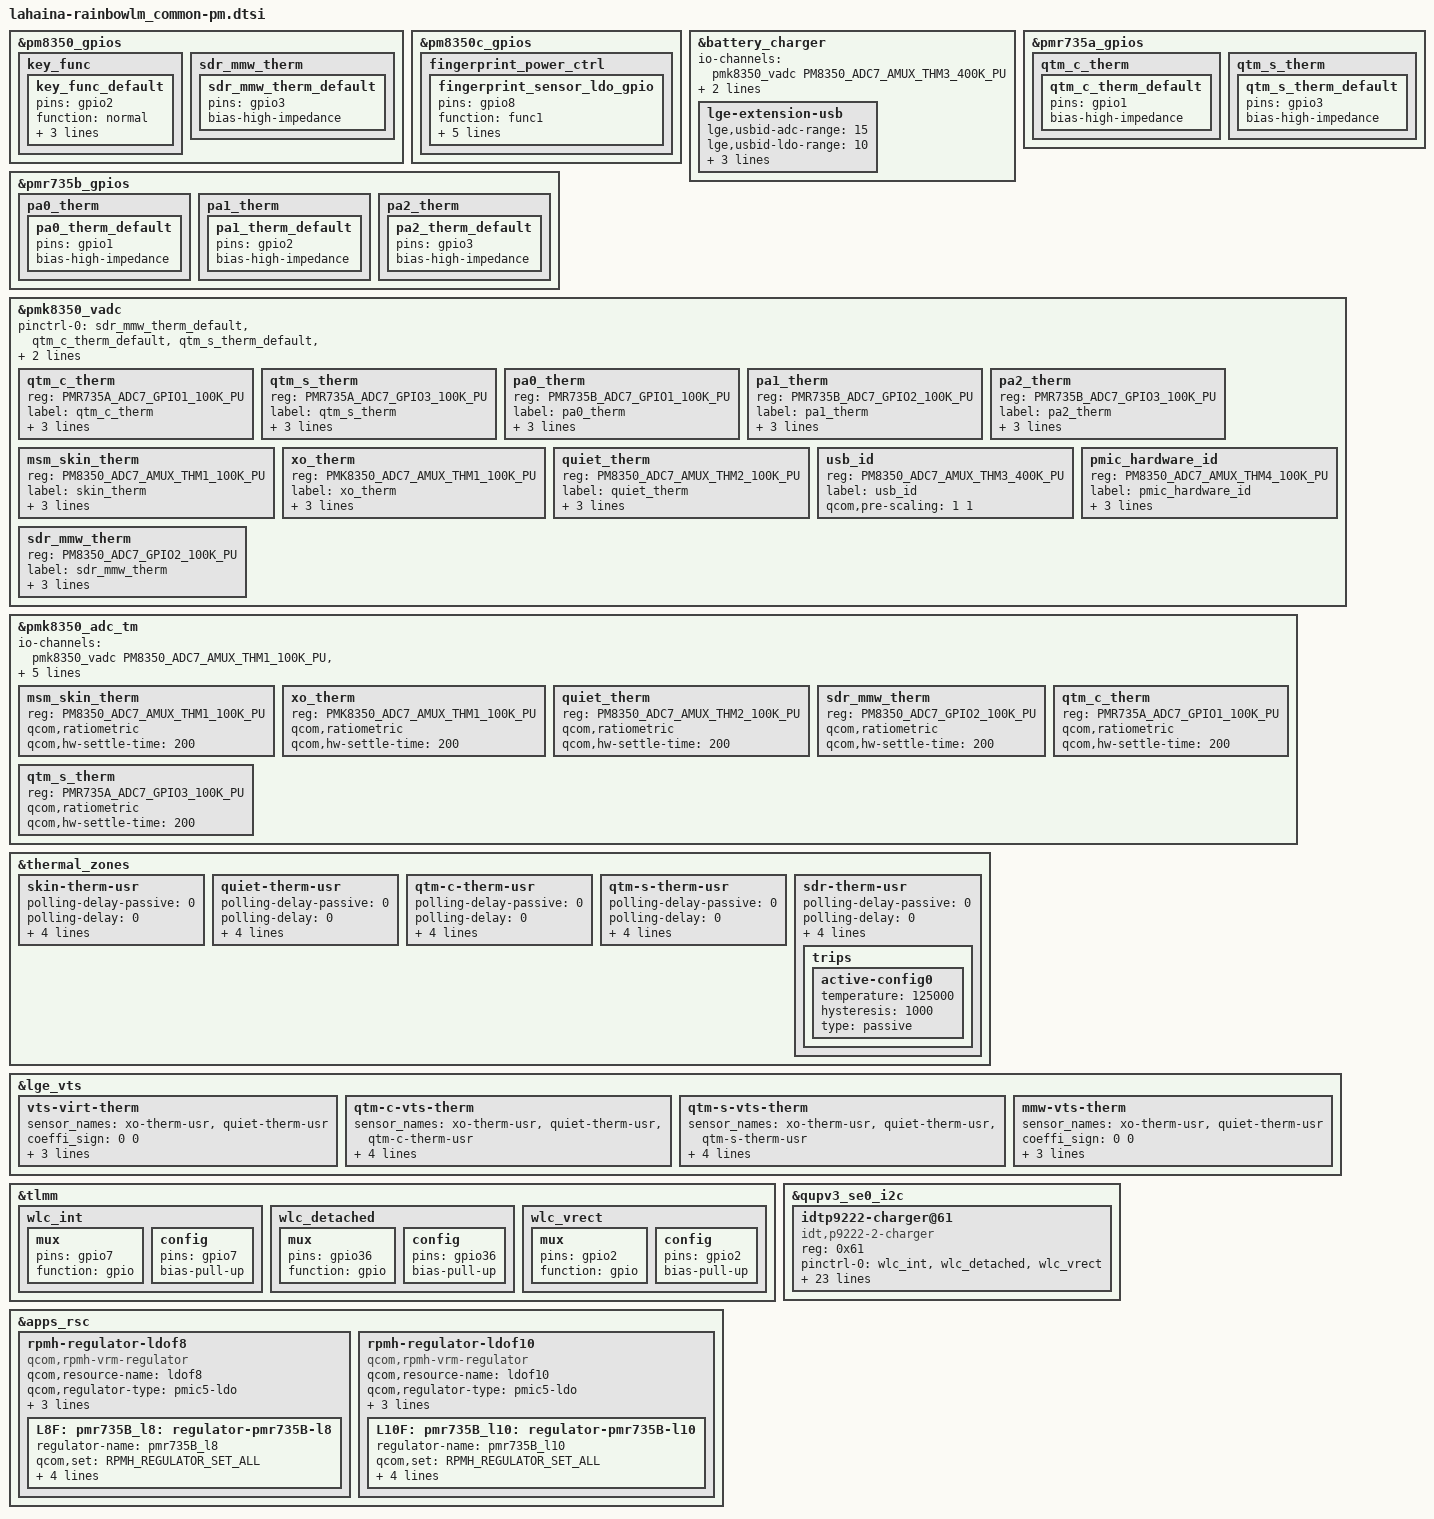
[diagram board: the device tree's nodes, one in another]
#include "../../lahaina_common/lahaina_common-pm.dtsi"
#include "../../lahaina_common/lahaina_common-veneer.dtsi"
#include "lahaina-rainbowlm_common-veneer.dtsi"
#include <dt-bindings/regulator/qcom,rpmh-regulator-levels.h>

&pm8350_gpios {
    key_func {
	key_func_default: key_func_default {
	    pins = "gpio2";
	    function = "normal";
	    input-enable;
	    bias-pull-up;
	    power-source = <0>;
	};
    };

	sdr_mmw_therm {
		sdr_mmw_therm_default: sdr_mmw_therm_default {
			pins = "gpio3";
			bias-high-impedance;
		};
	};
};

#if 1    // LGE_RAINBOW
&pm8350c_gpios {
    fingerprint_power_ctrl {
        fingerprint_sensor_ldo_gpio: fingerprint_sensor_ldo_gpio {
            pins = "gpio8";
            function = "func1";
            input-disable;
            output-enable;
            bias-disable;
            power-source = <1>;	/* 1.8V */
            qcom,drive-strength = <2>;
        };
    };
};
#endif

&battery_charger {
	io-channels = <&pmk8350_vadc PM8350_ADC7_AMUX_THM3_400K_PU>;
	io-channel-names = "usb_id";

	/delete-property/ qcom,thermal-mitigation;

	lge,hvdcp-disable-jp;
	lge,pcb-battery-id = <390000>;
	lge-extension-usb {
		lge,usbid-adc-range = <15>;		// ADC margin (pct unit)
		lge,usbid-ldo-range = <10>;		// LDO margin (pct unit)
		lge,usbid-pullup-mvol = <1800>;		// Pull-up voltage
		lge,usbid-pullup-kohm = <400>;		// Pull-up resistance
		lge,usbid-parallel-kohm = <(-1)>;	// Pull-up resistance
	};
};

&pmr735a_gpios {
	qtm_c_therm {
		qtm_c_therm_default: qtm_c_therm_default {
			pins = "gpio1";
			bias-high-impedance;
		};
	};

	qtm_s_therm {
		qtm_s_therm_default: qtm_s_therm_default {
			pins = "gpio3";
			bias-high-impedance;
		};
	};
};

&pmr735b_gpios {
	pa0_therm {
		pa0_therm_default: pa0_therm_default {
			pins = "gpio1";
			bias-high-impedance;
		};
	};

	pa1_therm {
		pa1_therm_default: pa1_therm_default {
			pins = "gpio2";
			bias-high-impedance;
		};
	};

	pa2_therm {
		pa2_therm_default: pa2_therm_default {
			pins = "gpio3";
			bias-high-impedance;
		};
	};
};

&pmk8350_vadc {
	pinctrl-names = "default";
	pinctrl-0 = <&sdr_mmw_therm_default
		&qtm_c_therm_default
		&qtm_s_therm_default
		&pa0_therm_default
		&pa1_therm_default
		&pa2_therm_default>;

	qtm_c_therm {
		reg = <PMR735A_ADC7_GPIO1_100K_PU>;
		label = "qtm_c_therm";
		qcom,ratiometric;
		qcom,hw-settle-time = <200>;
		qcom,pre-scaling = <1 1>;
	};

	qtm_s_therm {
		reg = <PMR735A_ADC7_GPIO3_100K_PU>;
		label = "qtm_s_therm";
		qcom,ratiometric;
		qcom,hw-settle-time = <200>;
		qcom,pre-scaling = <1 1>;
	};

	pa0_therm {
		reg = <PMR735B_ADC7_GPIO1_100K_PU>;
		label = "pa0_therm";
		qcom,ratiometric;
		qcom,hw-settle-time = <200>;
		qcom,pre-scaling = <1 1>;
	};

	pa1_therm {
		reg = <PMR735B_ADC7_GPIO2_100K_PU>;
		label = "pa1_therm";
		qcom,ratiometric;
		qcom,hw-settle-time = <200>;
		qcom,pre-scaling = <1 1>;
	};

	pa2_therm {
		reg = <PMR735B_ADC7_GPIO3_100K_PU>;
		label = "pa2_therm";
		qcom,ratiometric;
		qcom,hw-settle-time = <200>;
		qcom,pre-scaling = <1 1>;
	};

	msm_skin_therm {
		reg = <PM8350_ADC7_AMUX_THM1_100K_PU>;
		label = "skin_therm";
		qcom,ratiometric;
		qcom,hw-settle-time = <200>;
		qcom,pre-scaling = <1 1>;
	};

	xo_therm {
		reg = <PMK8350_ADC7_AMUX_THM1_100K_PU>;
		label = "xo_therm";
		qcom,ratiometric;
		qcom,hw-settle-time = <200>;
		qcom,pre-scaling = <1 1>;
	};

	quiet_therm {
		reg = <PM8350_ADC7_AMUX_THM2_100K_PU>;
		label = "quiet_therm";
		qcom,ratiometric;
		qcom,hw-settle-time = <200>;
		qcom,pre-scaling = <1 1>;
	};

	usb_id {
		reg = <PM8350_ADC7_AMUX_THM3_400K_PU>;
		label = "usb_id";
		qcom,pre-scaling = <1 1>;
	};

	pmic_hardware_id {
		reg = <PM8350_ADC7_AMUX_THM4_100K_PU>;
		label = "pmic_hardware_id";
		qcom,ratiometric;
		qcom,hw-settle-time = <100>;
		qcom,pre-scaling = <1 1>;
	};

	sdr_mmw_therm {
		reg = <PM8350_ADC7_GPIO2_100K_PU>;
		label = "sdr_mmw_therm";
		qcom,ratiometric;
		qcom,hw-settle-time = <200>;
		qcom,pre-scaling = <1 1>;
	};
};

&pmk8350_adc_tm {
	io-channels = <&pmk8350_vadc PM8350_ADC7_AMUX_THM1_100K_PU>,
		<&pmk8350_vadc PMK8350_ADC7_AMUX_THM1_100K_PU>,
		<&pmk8350_vadc PM8350_ADC7_AMUX_THM2_100K_PU>,
		<&pmk8350_vadc PM8350_ADC7_GPIO2_100K_PU>,
		<&pmk8350_vadc PMR735A_ADC7_GPIO1_100K_PU>,
		<&pmk8350_vadc PMR735A_ADC7_GPIO3_100K_PU>;

	msm_skin_therm {
		reg = <PM8350_ADC7_AMUX_THM1_100K_PU>;
		qcom,ratiometric;
		qcom,hw-settle-time = <200>;
	};

	xo_therm {
		reg = <PMK8350_ADC7_AMUX_THM1_100K_PU>;
		qcom,ratiometric;
		qcom,hw-settle-time = <200>;
	};

	quiet_therm {
		reg = <PM8350_ADC7_AMUX_THM2_100K_PU>;
		qcom,ratiometric;
		qcom,hw-settle-time = <200>;
	};

	sdr_mmw_therm {
		reg = <PM8350_ADC7_GPIO2_100K_PU>;
		qcom,ratiometric;
		qcom,hw-settle-time = <200>;
	};

	qtm_c_therm {
		reg = <PMR735A_ADC7_GPIO1_100K_PU>;
		qcom,ratiometric;
		qcom,hw-settle-time = <200>;
	};

	qtm_s_therm {
		reg = <PMR735A_ADC7_GPIO3_100K_PU>;
		qcom,ratiometric;
		qcom,hw-settle-time = <200>;
	};

};

&thermal_zones {
	skin-therm-usr {
		polling-delay-passive = <0>;
		polling-delay = <0>;
		thermal-governor = "user_space";
		thermal-sensors = <&pmk8350_adc_tm PM8350_ADC7_AMUX_THM1_100K_PU>;
		wake-capable-sensor;
	};

	quiet-therm-usr {
		polling-delay-passive = <0>;
		polling-delay = <0>;
		thermal-governor = "user_space";
		thermal-sensors = <&pmk8350_adc_tm PM8350_ADC7_AMUX_THM2_100K_PU>;
		wake-capable-sensor;
	};

	qtm-c-therm-usr {
		polling-delay-passive = <0>;
		polling-delay = <0>;
		thermal-governor = "user_space";
		thermal-sensors = <&pmk8350_adc_tm PMR735A_ADC7_GPIO1_100K_PU>;
		wake-capable-sensor;
	};

	qtm-s-therm-usr {
		polling-delay-passive = <0>;
		polling-delay = <0>;
		thermal-governor = "user_space";
		thermal-sensors = <&pmk8350_adc_tm PMR735A_ADC7_GPIO3_100K_PU>;
		wake-capable-sensor;
	};

	sdr-therm-usr {
		polling-delay-passive = <0>;
		polling-delay = <0>;
		thermal-governor = "user_space";
		thermal-sensors = <&pmk8350_adc_tm PM8350_ADC7_GPIO2_100K_PU>;
		wake-capable-sensor;
		trips {
			active-config0 {
				temperature = <125000>;
				hysteresis = <1000>;
				type = "passive";
			};
		};
	};
};


&lge_vts {
	vts-virt-therm {
		sensor_names = "xo-therm-usr", "quiet-therm-usr";
		coeffi_sign = <0 0>;
		coefficients = <391 388>;
		avg_denominator = <1000>;
		avg_offset = <4795>;
	};
	qtm-c-vts-therm {
		sensor_names = "xo-therm-usr", "quiet-therm-usr", "qtm-c-therm-usr";
		coeffi_sign = <0 0 0>;
		coefficients = <80 612 119>;
		avg_denominator = <1000>;
		avg_offset = <3713>;
	};
	qtm-s-vts-therm {
		sensor_names = "xo-therm-usr", "quiet-therm-usr", "qtm-s-therm-usr";
		coeffi_sign = <0 0 1>;
		coefficients = <877 84 212>;
		avg_denominator = <1000>;
		avg_offset = <4541>;
	};
	mmw-vts-therm {
		sensor_names = "xo-therm-usr", "quiet-therm-usr";
		coeffi_sign = <0 0>;
		coefficients = <320 493>;
		avg_denominator = <1000>;
		avg_offset = <3520>;
	};

};

&tlmm {
	wlc_int: wlc_int {
		mux {
			pins = "gpio7";
			function = "gpio";
		};

		config {
			pins = "gpio7";
			bias-pull-up;
		};
	};

	wlc_detached: wlc_detached {
		mux {
			pins = "gpio36";
			function = "gpio";
		};

		config {
			pins = "gpio36";
			bias-pull-up;
		};
	};

	wlc_vrect: wlc_vrect {
		mux {
			pins = "gpio2";
			function = "gpio";
		};

		config {
			pins = "gpio2";
			bias-pull-up;
		};
	};
};

&qupv3_se0_i2c {
	status = "ok";
	idtp9222-charger@61 {
		compatible ="idt,p9222-2-charger";
		reg = <0x61>;
		status = "ok";

		pinctrl-names = "wlc_pinctrl";
		pinctrl-0 = <&wlc_int &wlc_detached &wlc_vrect>;

		idt,gpio-int = <&tlmm 7 0>;
		idt,gpio-detached = <&tlmm 36 0>;
		idt,gpio-vrect = <&tlmm 2 0>;

		idt,fod-epp = [ A5 3B 88 44
			86 46 96 19
			96 05 97 05
			14 00 A0 55 ];
		idt,fod-bpp = [ A5 28 88 2E
			98 19 A3 03
			A0 09 A8 E8
			14 00 00 3C ];

		idt,probation-temp = <290 300 310 320 330 340 380 390 400>;
		idt,probation-curr = <1000 900 800 900 800 700 650 550 450>;
		idt,probation-volt = <12000 12000 12000 9000 9000 9000 9000 9000 9000>;

		idt,configure-bppcurr = <900>;
		idt,configure-bppvolt = <5500>;
		idt,configure-eppcurr = <900>;
		idt,configure-eppvolt = <9000>;
		idt,configure-maxcurr = <1000>;
		idt,configure-maxvolt = <12000>;
		idt,configure-fullcurr = <500>;
		idt,configure-overheat = <450>;
		idt,configure-sysfs;
		idt,configure-qbg;
		//idt,configure-charge-done;
	};
};

&apps_rsc {
	rpmh-regulator-ldof8 {
		compatible = "qcom,rpmh-vrm-regulator";
		qcom,resource-name = "ldof8";
		qcom,regulator-type = "pmic5-ldo";
		qcom,supported-modes =
			<RPMH_REGULATOR_MODE_LPM
			RPMH_REGULATOR_MODE_HPM>;
		qcom,mode-threshold-currents = <0 30000>;
		L8F: pmr735B_l8: regulator-pmr735B-l8 {
			regulator-name = "pmr735B_l8";
			qcom,set = <RPMH_REGULATOR_SET_ALL>;
			regulator-min-microvolt = <1100000>;
			regulator-max-microvolt = <1100000>;
			qcom,init-voltage = <1100000>;
			qcom,init-mode = <RPMH_REGULATOR_MODE_HPM>;
		};
	};

	rpmh-regulator-ldof10 {
		compatible = "qcom,rpmh-vrm-regulator";
		qcom,resource-name = "ldof10";
		qcom,regulator-type = "pmic5-ldo";
		qcom,supported-modes =
			<RPMH_REGULATOR_MODE_LPM
			RPMH_REGULATOR_MODE_HPM>;
		qcom,mode-threshold-currents = <0 30000>;
		L10F: pmr735B_l10: regulator-pmr735B-l10 {
			regulator-name = "pmr735B_l10";
			qcom,set = <RPMH_REGULATOR_SET_ALL>;
			regulator-min-microvolt = <1800000>;
			regulator-max-microvolt = <1800000>;
			qcom,init-voltage = <1800000>;
			qcom,init-mode = <RPMH_REGULATOR_MODE_HPM>;
		};
	};
};
